# CC3200 register map
Vendor: Texas Instruments; Series: SimpleLink; File version: 1.0
CPU: CM4 r0p1, little endian, MPU, no FPU, 3 interrupt priority bits
Registers are 32-bit, read-write, reset 0x0 unless marked. A register's access mark holds for its fields unless they carry their own. Offsets are from the block's base; [hi:lo] are bit positions.

## APPS_CONFIG
Base 0x44026000
0x00 PATCH_TRAP_ADDR_REG — APPS_CONFIG_PATCH_TRAP_ADDR_REG
  [31:0] PATCH_TRAP_ADDR_M
0x78 PATCH_TRAP_EN_REG — APPS_CONFIG_PATCH_TRAP_EN_REG
  [29:0] PATCH_TRAP_EN_M
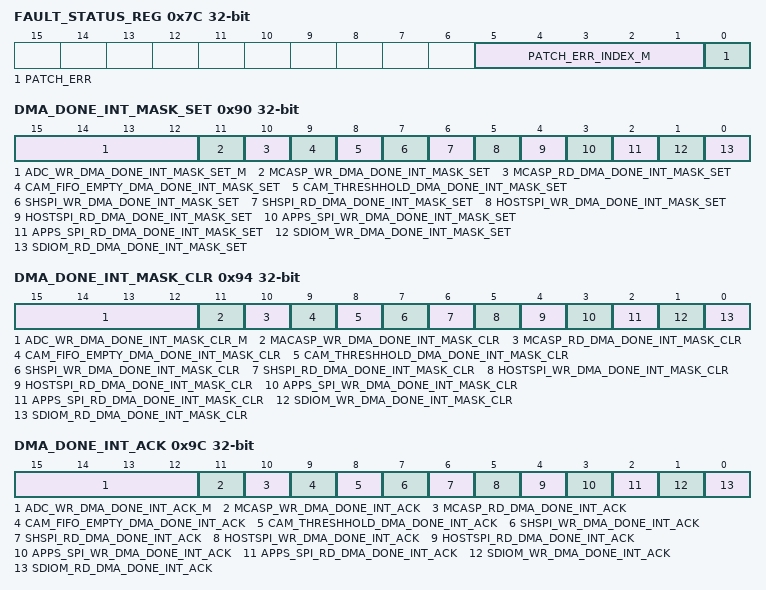
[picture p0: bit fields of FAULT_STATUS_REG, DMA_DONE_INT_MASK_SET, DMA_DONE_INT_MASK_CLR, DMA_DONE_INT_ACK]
0x7C FAULT_STATUS_REG — APPS_CONFIG_FAULT_STATUS_REG
  [5:1] PATCH_ERR_INDEX_M — APPS_CONFIG_FAULT_STATUS_REG
  [0] PATCH_ERR — APPS_CONFIG_FAULT_STATUS_REG
0x80 MEMSS_WR_ERR_CLR_REG — APPS_CONFIG_MEMSS_WR_ERR_CLR_REG
  [0] MEMSS_WR_ERR_CLR
0x84 MEMSS_WR_ERR_ADDR_REG — APPS_CONFIG_MEMSS_WR_ERR_ADDR_REG
0x8C DMA_DONE_INT_MASK — APPS_CONFIG_DMA_DONE_INT_MASK
  [15:12] ADC_WR_DMA_DONE_INT_MASK_M — APPS_CONFIG_DMA_DONE_INT_MASK
  [15:12] CLR_ADC_WR_DMA_DONE_INT_MASK_CLR_M — APPS_CONFIG_DMA_DONE_INT_MASK
  [15:12] SET_ADC_WR_DMA_DONE_INT_MASK_SET_M — APPS_CONFIG_DMA_DONE_INT_MASK
  [11] CLR_MACASP_WR_DMA_DONE_INT_MASK_CLR — APPS_CONFIG_DMA_DONE_INT_MASK
  [11] MCASP_WR_DMA_DONE_INT_MASK — APPS_CONFIG_DMA_DONE_INT_MASK
  [11] SET_MCASP_WR_DMA_DONE_INT_MASK_SET — APPS_CONFIG_DMA_DONE_INT_MASK
  [10] CLR_MCASP_RD_DMA_DONE_INT_MASK_CLR — APPS_CONFIG_DMA_DONE_INT_MASK
  [10] MCASP_RD_DMA_DONE_INT_MASK — APPS_CONFIG_DMA_DONE_INT_MASK
  [10] SET_MCASP_RD_DMA_DONE_INT_MASK_SET — APPS_CONFIG_DMA_DONE_INT_MASK
  [9] CAM_FIFO_EMPTY_DMA_DONE_INT_MASK — APPS_CONFIG_DMA_DONE_INT_MASK
  [9] CLR_CAM_FIFO_EMPTY_DMA_DONE_INT_MASK_CLR — APPS_CONFIG_DMA_DONE_INT_MASK
  [9] SET_CAM_FIFO_EMPTY_DMA_DONE_INT_MASK_SET — APPS_CONFIG_DMA_DONE_INT_MASK
  [8] CAM_THRESHHOLD_DMA_DONE_INT_MASK — APPS_CONFIG_DMA_DONE_INT_MASK
  [8] CLR_CAM_THRESHHOLD_DMA_DONE_INT_MASK_CLR — APPS_CONFIG_DMA_DONE_INT_MASK
  [8] SET_CAM_THRESHHOLD_DMA_DONE_INT_MASK_SET — APPS_CONFIG_DMA_DONE_INT_MASK
  [7] CLR_SHSPI_WR_DMA_DONE_INT_MASK_CLR — APPS_CONFIG_DMA_DONE_INT_MASK
  [7] SET_SHSPI_WR_DMA_DONE_INT_MASK_SET — APPS_CONFIG_DMA_DONE_INT_MASK
  [7] SHSPI_WR_DMA_DONE_INT_MASK — APPS_CONFIG_DMA_DONE_INT_MASK
  [6] CLR_SHSPI_RD_DMA_DONE_INT_MASK_CLR — APPS_CONFIG_DMA_DONE_INT_MASK
  [6] SET_SHSPI_RD_DMA_DONE_INT_MASK_SET — APPS_CONFIG_DMA_DONE_INT_MASK
  [6] SHSPI_RD_DMA_DONE_INT_MASK — APPS_CONFIG_DMA_DONE_INT_MASK
  [5] CLR_HOSTSPI_WR_DMA_DONE_INT_MASK_CLR — APPS_CONFIG_DMA_DONE_INT_MASK
  [5] HOSTSPI_WR_DMA_DONE_INT_MASK — APPS_CONFIG_DMA_DONE_INT_MASK
  [5] SET_HOSTSPI_WR_DMA_DONE_INT_MASK_SET — APPS_CONFIG_DMA_DONE_INT_MASK
  [4] CLR_HOSTSPI_RD_DMA_DONE_INT_MASK_CLR — APPS_CONFIG_DMA_DONE_INT_MASK
  [4] HOSTSPI_RD_DMA_DONE_INT_MASK — APPS_CONFIG_DMA_DONE_INT_MASK
  [4] SET_HOSTSPI_RD_DMA_DONE_INT_MASK_SET — APPS_CONFIG_DMA_DONE_INT_MASK
  [3] APPS_SPI_WR_DMA_DONE_INT_MASK — APPS_CONFIG_DMA_DONE_INT_MASK
  [3] CLR_APPS_SPI_WR_DMA_DONE_INT_MASK_CLR — APPS_CONFIG_DMA_DONE_INT_MASK
  [3] SET_APPS_SPI_WR_DMA_DONE_INT_MASK_SET — APPS_CONFIG_DMA_DONE_INT_MASK
  [2] APPS_SPI_RD_DMA_DONE_INT_MASK — APPS_CONFIG_DMA_DONE_INT_MASK
  [2] CLR_APPS_SPI_RD_DMA_DONE_INT_MASK_CLR — APPS_CONFIG_DMA_DONE_INT_MASK
  [2] SET_APPS_SPI_RD_DMA_DONE_INT_MASK_SET — APPS_CONFIG_DMA_DONE_INT_MASK
  [1] CLR_SDIOM_WR_DMA_DONE_INT_MASK_CLR — APPS_CONFIG_DMA_DONE_INT_MASK
  [1] SDIOM_WR_DMA_DONE_INT_MASK — APPS_CONFIG_DMA_DONE_INT_MASK
  [1] SET_SDIOM_WR_DMA_DONE_INT_MASK_SET — APPS_CONFIG_DMA_DONE_INT_MASK
  [0] CLR_SDIOM_RD_DMA_DONE_INT_MASK_CLR — APPS_CONFIG_DMA_DONE_INT_MASK
  [0] SDIOM_RD_DMA_DONE_INT_MASK — APPS_CONFIG_DMA_DONE_INT_MASK
  [0] SET_SDIOM_RD_DMA_DONE_INT_MASK_SET — APPS_CONFIG_DMA_DONE_INT_MASK
0x90 DMA_DONE_INT_MASK_SET — APPS_CONFIG_DMA_DONE_INT_MASK_SET
  [15:12] ADC_WR_DMA_DONE_INT_MASK_SET_M — APPS_CONFIG_DMA_DONE_INT_MASK_SET
  [11] MCASP_WR_DMA_DONE_INT_MASK_SET — APPS_CONFIG_DMA_DONE_INT_MASK_SET
  [10] MCASP_RD_DMA_DONE_INT_MASK_SET — APPS_CONFIG_DMA_DONE_INT_MASK_SET
  [9] CAM_FIFO_EMPTY_DMA_DONE_INT_MASK_SET — APPS_CONFIG_DMA_DONE_INT_MASK_SET
  [8] CAM_THRESHHOLD_DMA_DONE_INT_MASK_SET — APPS_CONFIG_DMA_DONE_INT_MASK_SET
  [7] SHSPI_WR_DMA_DONE_INT_MASK_SET — APPS_CONFIG_DMA_DONE_INT_MASK_SET
  [6] SHSPI_RD_DMA_DONE_INT_MASK_SET — APPS_CONFIG_DMA_DONE_INT_MASK_SET
  [5] HOSTSPI_WR_DMA_DONE_INT_MASK_SET — APPS_CONFIG_DMA_DONE_INT_MASK_SET
  [4] HOSTSPI_RD_DMA_DONE_INT_MASK_SET — APPS_CONFIG_DMA_DONE_INT_MASK_SET
  [3] APPS_SPI_WR_DMA_DONE_INT_MASK_SET — APPS_CONFIG_DMA_DONE_INT_MASK_SET
  [2] APPS_SPI_RD_DMA_DONE_INT_MASK_SET — APPS_CONFIG_DMA_DONE_INT_MASK_SET
  [1] SDIOM_WR_DMA_DONE_INT_MASK_SET — APPS_CONFIG_DMA_DONE_INT_MASK_SET
  [0] SDIOM_RD_DMA_DONE_INT_MASK_SET — APPS_CONFIG_DMA_DONE_INT_MASK_SET
0x94 DMA_DONE_INT_MASK_CLR — APPS_CONFIG_DMA_DONE_INT_MASK_CLR
  [15:12] ADC_WR_DMA_DONE_INT_MASK_CLR_M — APPS_CONFIG_DMA_DONE_INT_MASK_CLR
  [11] MACASP_WR_DMA_DONE_INT_MASK_CLR — APPS_CONFIG_DMA_DONE_INT_MASK_CLR
  [10] MCASP_RD_DMA_DONE_INT_MASK_CLR — APPS_CONFIG_DMA_DONE_INT_MASK_CLR
  [9] CAM_FIFO_EMPTY_DMA_DONE_INT_MASK_CLR — APPS_CONFIG_DMA_DONE_INT_MASK_CLR
  [8] CAM_THRESHHOLD_DMA_DONE_INT_MASK_CLR — APPS_CONFIG_DMA_DONE_INT_MASK_CLR
  [7] SHSPI_WR_DMA_DONE_INT_MASK_CLR — APPS_CONFIG_DMA_DONE_INT_MASK_CLR
  [6] SHSPI_RD_DMA_DONE_INT_MASK_CLR — APPS_CONFIG_DMA_DONE_INT_MASK_CLR
  [5] HOSTSPI_WR_DMA_DONE_INT_MASK_CLR — APPS_CONFIG_DMA_DONE_INT_MASK_CLR
  [4] HOSTSPI_RD_DMA_DONE_INT_MASK_CLR — APPS_CONFIG_DMA_DONE_INT_MASK_CLR
  [3] APPS_SPI_WR_DMA_DONE_INT_MASK_CLR — APPS_CONFIG_DMA_DONE_INT_MASK_CLR
  [2] APPS_SPI_RD_DMA_DONE_INT_MASK_CLR — APPS_CONFIG_DMA_DONE_INT_MASK_CLR
  [1] SDIOM_WR_DMA_DONE_INT_MASK_CLR — APPS_CONFIG_DMA_DONE_INT_MASK_CLR
  [0] SDIOM_RD_DMA_DONE_INT_MASK_CLR — APPS_CONFIG_DMA_DONE_INT_MASK_CLR
0x98 DMA_DONE_INT_STS_CLR — APPS_CONFIG_DMA_DONE_INT_STS_CLR
  [31:0] DMA_INT_STS_CLR_M
0x9C DMA_DONE_INT_ACK — APPS_CONFIG_DMA_DONE_INT_ACK
  [15:12] ADC_WR_DMA_DONE_INT_ACK_M — APPS_CONFIG_DMA_DONE_INT_ACK
  [11] MCASP_WR_DMA_DONE_INT_ACK — APPS_CONFIG_DMA_DONE_INT_ACK
  [10] MCASP_RD_DMA_DONE_INT_ACK — APPS_CONFIG_DMA_DONE_INT_ACK
  [9] CAM_FIFO_EMPTY_DMA_DONE_INT_ACK — APPS_CONFIG_DMA_DONE_INT_ACK
  [8] CAM_THRESHHOLD_DMA_DONE_INT_ACK — APPS_CONFIG_DMA_DONE_INT_ACK
  [7] SHSPI_WR_DMA_DONE_INT_ACK — APPS_CONFIG_DMA_DONE_INT_ACK
  [6] SHSPI_RD_DMA_DONE_INT_ACK — APPS_CONFIG_DMA_DONE_INT_ACK
  [5] HOSTSPI_WR_DMA_DONE_INT_ACK — APPS_CONFIG_DMA_DONE_INT_ACK
  [4] HOSTSPI_RD_DMA_DONE_INT_ACK — APPS_CONFIG_DMA_DONE_INT_ACK
  [3] APPS_SPI_WR_DMA_DONE_INT_ACK — APPS_CONFIG_DMA_DONE_INT_ACK
  [2] APPS_SPI_RD_DMA_DONE_INT_ACK — APPS_CONFIG_DMA_DONE_INT_ACK
  [1] SDIOM_WR_DMA_DONE_INT_ACK — APPS_CONFIG_DMA_DONE_INT_ACK
  [0] SDIOM_RD_DMA_DONE_INT_ACK — APPS_CONFIG_DMA_DONE_INT_ACK
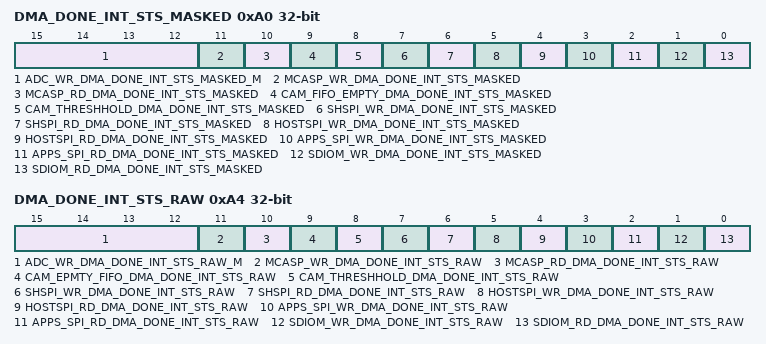
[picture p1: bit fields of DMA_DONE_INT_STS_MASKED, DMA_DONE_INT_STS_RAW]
0xA0 DMA_DONE_INT_STS_MASKED — APPS_CONFIG_DMA_DONE_INT_STS_MASKED
  [15:12] ADC_WR_DMA_DONE_INT_STS_MASKED_M — APPS_CONFIG_DMA_DONE_INT_STS_MASKED
  [11] MCASP_WR_DMA_DONE_INT_STS_MASKED — APPS_CONFIG_DMA_DONE_INT_STS_MASKED
  [10] MCASP_RD_DMA_DONE_INT_STS_MASKED — APPS_CONFIG_DMA_DONE_INT_STS_MASKED
  [9] CAM_FIFO_EMPTY_DMA_DONE_INT_STS_MASKED — APPS_CONFIG_DMA_DONE_INT_STS_MASKED
  [8] CAM_THRESHHOLD_DMA_DONE_INT_STS_MASKED — APPS_CONFIG_DMA_DONE_INT_STS_MASKED
  [7] SHSPI_WR_DMA_DONE_INT_STS_MASKED — APPS_CONFIG_DMA_DONE_INT_STS_MASKED
  [6] SHSPI_RD_DMA_DONE_INT_STS_MASKED — APPS_CONFIG_DMA_DONE_INT_STS_MASKED
  [5] HOSTSPI_WR_DMA_DONE_INT_STS_MASKED — APPS_CONFIG_DMA_DONE_INT_STS_MASKED
  [4] HOSTSPI_RD_DMA_DONE_INT_STS_MASKED — APPS_CONFIG_DMA_DONE_INT_STS_MASKED
  [3] APPS_SPI_WR_DMA_DONE_INT_STS_MASKED — APPS_CONFIG_DMA_DONE_INT_STS_MASKED
  [2] APPS_SPI_RD_DMA_DONE_INT_STS_MASKED — APPS_CONFIG_DMA_DONE_INT_STS_MASKED
  [1] SDIOM_WR_DMA_DONE_INT_STS_MASKED — APPS_CONFIG_DMA_DONE_INT_STS_MASKED
  [0] SDIOM_RD_DMA_DONE_INT_STS_MASKED — APPS_CONFIG_DMA_DONE_INT_STS_MASKED
0xA4 DMA_DONE_INT_STS_RAW — APPS_CONFIG_DMA_DONE_INT_STS_RAW
  [15:12] ADC_WR_DMA_DONE_INT_STS_RAW_M — APPS_CONFIG_DMA_DONE_INT_STS_RAW
  [11] MCASP_WR_DMA_DONE_INT_STS_RAW — APPS_CONFIG_DMA_DONE_INT_STS_RAW
  [10] MCASP_RD_DMA_DONE_INT_STS_RAW — APPS_CONFIG_DMA_DONE_INT_STS_RAW
  [9] CAM_EPMTY_FIFO_DMA_DONE_INT_STS_RAW — APPS_CONFIG_DMA_DONE_INT_STS_RAW
  [8] CAM_THRESHHOLD_DMA_DONE_INT_STS_RAW — APPS_CONFIG_DMA_DONE_INT_STS_RAW
  [7] SHSPI_WR_DMA_DONE_INT_STS_RAW — APPS_CONFIG_DMA_DONE_INT_STS_RAW
  [6] SHSPI_RD_DMA_DONE_INT_STS_RAW — APPS_CONFIG_DMA_DONE_INT_STS_RAW
  [5] HOSTSPI_WR_DMA_DONE_INT_STS_RAW — APPS_CONFIG_DMA_DONE_INT_STS_RAW
  [4] HOSTSPI_RD_DMA_DONE_INT_STS_RAW — APPS_CONFIG_DMA_DONE_INT_STS_RAW
  [3] APPS_SPI_WR_DMA_DONE_INT_STS_RAW — APPS_CONFIG_DMA_DONE_INT_STS_RAW
  [2] APPS_SPI_RD_DMA_DONE_INT_STS_RAW — APPS_CONFIG_DMA_DONE_INT_STS_RAW
  [1] SDIOM_WR_DMA_DONE_INT_STS_RAW — APPS_CONFIG_DMA_DONE_INT_STS_RAW
  [0] SDIOM_RD_DMA_DONE_INT_STS_RAW — APPS_CONFIG_DMA_DONE_INT_STS_RAW
0xA8 FAULT_STATUS_CLR_REG — APPS_CONFIG_FAULT_STATUS_CLR_REG
  [0] PATCH_ERR_CLR
0xAC RESERVD_REG_0 — APPS_CONFIG_RESERVD_REG_0
0xB0 GPT_TRIG_SEL — APPS_CONFIG_GPT_TRIG_SEL
  [7:0] GPT_TRIG_SEL_M
0xB4 TOP_DIE_SPARE_DIN_REG — APPS_CONFIG_TOP_DIE_SPARE_DIN_REG
  [2:0] D2D_SPARE_DIN_M
0xB8 TOP_DIE_SPARE_DOUT_REG — APPS_CONFIG_TOP_DIE_SPARE_DOUT_REG
  [2:0] D2D_SPARE_DOUT_M
